# PY32F002Axx register map
Vendor: Puya; Series: PY32F0; File version: 1.0.0
CPU: CM0+ r0p1, little endian, no MPU, no FPU, 4 interrupt priority bits
Registers are 32-bit, read-write, reset 0x0 unless marked. A register's access mark holds for its fields unless they carry their own. Offsets are from the block's base; [hi:lo] are bit positions; {n}, {i} and the like mark numbered series.

## LPTIM — Low power timer
Base 0x40007C00
0x00 ISR ro — Interrupt and Status Register
  [1] ARRM — Autoreload match
0x04 ICR wo — Interrupt Clear Register
  [1] ARRMCF — Autoreload match ClearFlag
0x08 IER — Interrupt Enable Register
  [1] ARRMIE — Autoreload match InterruptEnable
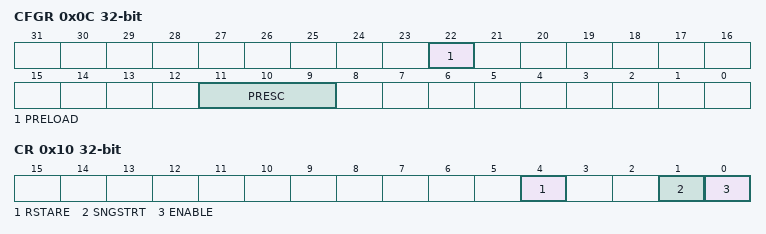
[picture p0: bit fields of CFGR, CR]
0x0C CFGR — Configuration Register
  [22] PRELOAD — Registers update mode
  [11:9] PRESC — Clock prescaler
    1=0; 2=1; 4=2
0x10 CR — Control Register
  [4] RSTARE — Reset after read enable
  [1] SNGSTRT — LPTIM start in single mode
  [0] ENABLE — LPTIM Enable
0x18 ARR reset 0x1 — Autoreload Register
  [15:0] ARR — Auto reload value
0x1C CNT ro — Counter Register
  [15:0] CNT — Counter value

## SPI1 — Serial peripheral interface
Base 0x40013000
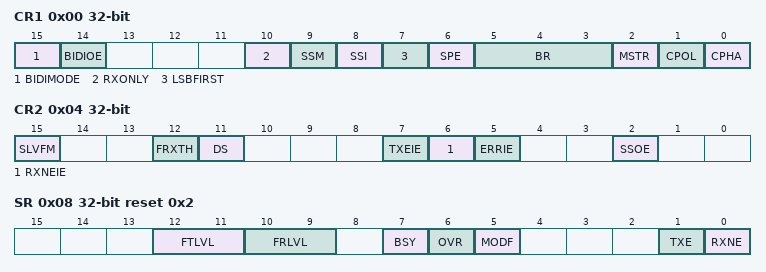
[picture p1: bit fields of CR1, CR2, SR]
0x00 CR1 — control register 1
  [15] BIDIMODE — Bidirectional data mode enable
  [14] BIDIOE — Output enable in bidirectional mode
  [10] RXONLY — Receive only
  [9] SSM — Software slave management
  [8] SSI — Internal slave selection
  [7] LSBFIRST — Frame format
  [6] SPE — SPI enable
  [5:3] BR — Baud rate control
    1=0; 2=1; 4=2
  [2] MSTR — Master selection
  [1] CPOL — Clock polarity
  [0] CPHA — Clock phase
0x04 CR2 — control register 2
  [15] SLVFM — Slave fast mode enable
  [12] FRXTH — FIFO reception threshold
  [11] DS — Data length
  [7] TXEIE — Tx buffer empty interrupt enable
  [6] RXNEIE — RX buffer not empty interrupt enable
  [5] ERRIE — Error interrupt enable
  [2] SSOE — SS output enable
0x08 SR reset 0x2 — status register
  [12:11] FTLVL ro — FIFO transmission level
    1=0; 2=1
  [10:9] FRLVL ro — FIFO reception level
    1=0; 2=1
  [7] BSY ro — Busy flag
  [6] OVR ro — Overrun flag
  [5] MODF ro — Mode fault
  [1] TXE ro — Transmit buffer empty
  [0] RXNE ro — Receive buffer not empty
0x0C DR — data register
  [15:0] DR — Data register

## SYSCFG — System configuration controller
Base 0x40010000
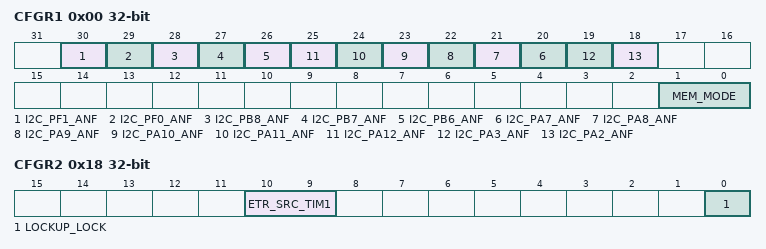
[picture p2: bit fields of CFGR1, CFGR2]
0x00 CFGR1 — SYSCFG configuration register1
  [30] I2C_PF1_ANF — Analog filter enable control driving capabilityactivation bits PF1
  [29] I2C_PF0_ANF — Analog filter enable control driving capabilityactivation bits PF0
  [28] I2C_PB8_ANF — Analog filter enable control driving capabilityactivation bits PB8
  [27] I2C_PB7_ANF — Analog filter enable control driving capabilityactivation bits PB7
  [26] I2C_PB6_ANF — Analog filter enable control driving capabilityactivation bits PB6
  [n+13] I2C_PA{n}_ANF (n=7..12) — Analog filter enable control driving capabilityactivation bits PA{n}
  [19] I2C_PA3_ANF — Analog filter enable control driving capabilityactivation bits PA3
  [18] I2C_PA2_ANF — Analog filter enable control driving capabilityactivation bits PA2
  [1:0] MEM_MODE — Memory mapping selectionbits
    1=0; 2=1
0x18 CFGR2 — SYSCFG configuration register2
  [10:9] ETR_SRC_TIM1 — TIM1 ETR source selection
    1=0; 2=1
  [0] LOCKUP_LOCK — Cortex-M0+ LOCKUP bit enablebit

## TIM16 — General purpose timer
Base 0x40014400
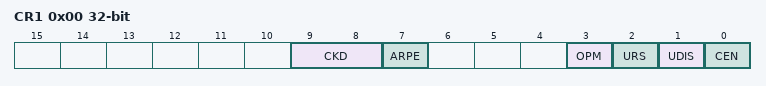
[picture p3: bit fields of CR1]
0x00 CR1 — TIM16 control register1
  [9:8] CKD — Prescaler factor
    1=0; 2=1
  [7] ARPE — Auto-reload preload enable
  [3] OPM — One pulse mode
  [2] URS — Update request source
  [1] UDIS — Update disable
  [0] CEN — Counter enable
0x0C DIER — DMA/Interrupt enable register
  [0] UIE — Update interrupt enable
0x10 SR — status register
  [0] UIF — Update interrupt flag
0x14 EGR wo — event generation register
  [0] UG — Update generation
0x24 CNT — counter
  [15:0] CNT — counter value
0x28 PSC — prescaler
  [15:0] PSC — Prescaler value
0x2C ARR — auto-reload register
  [15:0] ARR — Auto-reload value
0x30 RCR — repetition counter register
  [7:0] REP — Repetition counter value

## USART1 — Universal synchronous asynchronous receivertransmitter
Base 0x40013800
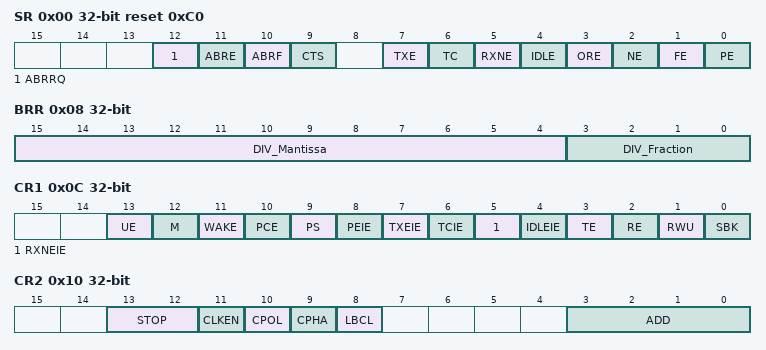
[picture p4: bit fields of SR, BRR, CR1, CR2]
0x00 SR reset 0xC0 — Status register
  [12] ABRRQ wo — Automate baudrate detection requeset
  [11] ABRE ro — Automate baudrate detection error flag
  [10] ABRF ro — Automate baudrate detection flag
  [9] CTS — CTS flag
  [7] TXE ro — Transmit data registerempty
  [6] TC — Transmission complete
  [5] RXNE — Read data register notempty
  [4] IDLE ro — IDLE line detected
  [3] ORE ro — Overrun error
  [2] NE ro — Noise error flag
  [1] FE ro — Framing error
  [0] PE ro — Parity error
0x04 DR — Data register
  [8:0] DR — Data value
0x08 BRR — Baud rate register
  [15:4] DIV_Mantissa — mantissa of USARTDIV
  [3:0] DIV_Fraction — fraction of USARTDIV
0x0C CR1 — Control register 1
  [13] UE — USART enable
  [12] M — Word length
  [11] WAKE — Wakeup method
  [10] PCE — Parity control enable
  [9] PS — Parity selection
  [8] PEIE — PE interrupt enable
  [7] TXEIE — TXE interrupt enable
  [6] TCIE — Transmission complete interruptenable
  [5] RXNEIE — RXNE interrupt enable
  [4] IDLEIE — IDLE interrupt enable
  [3] TE — Transmitter enable
  [2] RE — Receiver enable
  [1] RWU — Receiver wakeup
  [0] SBK — Send break
0x10 CR2 — Control register 2
  [13:12] STOP — STOP bits
  [11] CLKEN — Clock enable
  [10] CPOL — Clock polarity
  [9] CPHA — Clock phase
  [8] LBCL — Last bit clock pulse
  [3:0] ADD — Address of the USART node
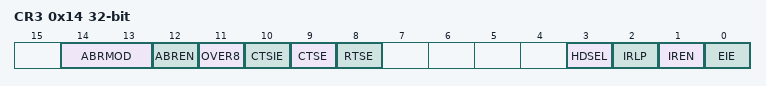
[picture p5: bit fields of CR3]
0x14 CR3 — Control register 3
  [14:13] ABRMOD — Auto baudrate mode
  [12] ABREN — Auto baudrate enable
  [11] OVER8 — Oversampling mode
  [10] CTSIE — CTS interrupt enable
  [9] CTSE — CTS enable
  [8] RTSE — RTS enable
  [3] HDSEL — Half-duplex selection
  [2] IRLP — IrDA low-power
  [1] IREN — IrDA mode enable
  [0] EIE — Error interrupt enable
